VERSION ""

NS_ :

BS_:

BU_: IZZE_SG_4E4

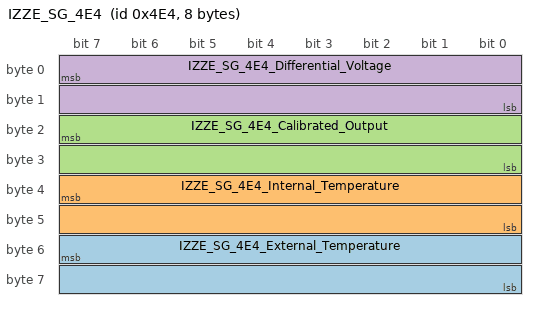
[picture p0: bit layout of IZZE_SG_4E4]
BO_ 1252 IZZE_SG_4E4: 8 IZZE_SG_4E4
 SG_ IZZE_SG_4E4_External_Temperature : 55|16@0- (0.1,0) [0|0] "C" Vector__XXX
 SG_ IZZE_SG_4E4_Internal_Temperature : 39|16@0- (0.1,0) [0|0] "C" Vector__XXX
 SG_ IZZE_SG_4E4_Calibrated_Output : 23|16@0- (0.1,0) [0|0] "F" Vector__XXX
 SG_ IZZE_SG_4E4_Differential_Voltage : 7|16@0- (1,0) [0|0] "µV" Vector__XXX

CM_ BO_ 1252 "Rear right IZZE - raw voltage, calibrated output, temperatures";
BA_DEF_  "BusType" STRING ;
BA_DEF_DEF_  "BusType" "";
BA_ "BusType" "CAN";
